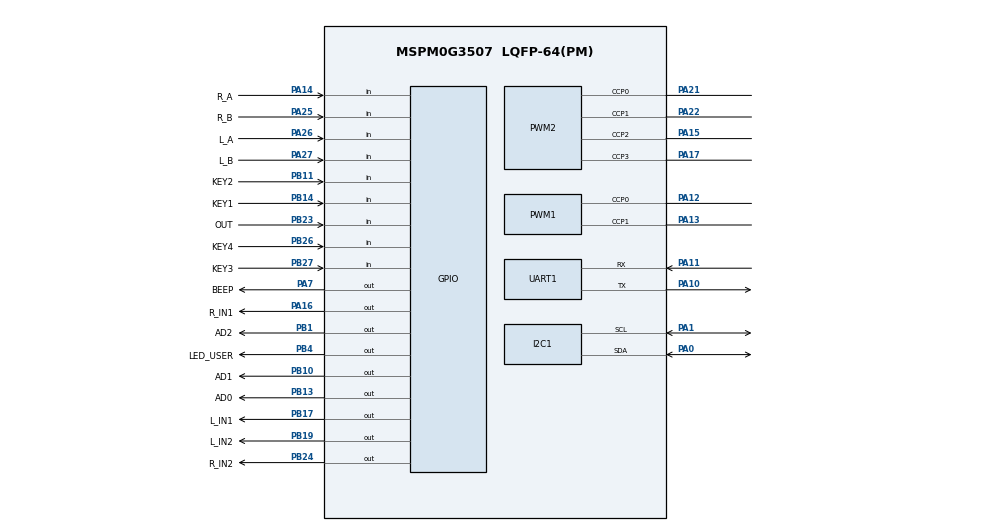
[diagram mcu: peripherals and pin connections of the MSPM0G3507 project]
/**
 * Revised local SysConfig script for the MSPM0G3507 E-car board.
 *
 * This file mirrors the checked-in ti_msp_dl_config.c/h logical names.
 * If SysConfig regenerates different macro names, keep App/Hardware code
 * mapped through Hardware/Board_Config.h.
 */
//@cliArgs --device "MSPM0G350X" --package "LQFP-64(PM)" --part "Default"
//@v2CliArgs --device "MSPM0G3507" --package "LQFP-64(PM)"
// @cliArgs --board /ti/boards/LP_MSPM0G3507 --rtos nortos

const GPIO   = scripting.addModule("/ti/driverlib/GPIO", {}, false);
const GPIO1  = GPIO.addInstance();
const GPIO2  = GPIO.addInstance();
const GPIO3  = GPIO.addInstance();
const GPIO4  = GPIO.addInstance();
const GPIO5  = GPIO.addInstance();
const I2C    = scripting.addModule("/ti/driverlib/I2C", {}, false);
const I2C1   = I2C.addInstance();
const PWM    = scripting.addModule("/ti/driverlib/PWM", {}, false);
const PWM1   = PWM.addInstance();
const PWM2   = PWM.addInstance();
const TIMER  = scripting.addModule("/ti/driverlib/TIMER", {}, false);
const TIMER1 = TIMER.addInstance();
const UART   = scripting.addModule("/ti/driverlib/UART", {}, false);
const UART1  = UART.addInstance();
const SYSCTL = scripting.addModule("/ti/driverlib/SYSCTL");

const Board = scripting.addModule("/ti/driverlib/Board", {}, false);

/*
 * TB6612:
 * PWMA = TIMG0-C0, PWMB = TIMG0-C1.
 * STBY is tied to 5V and is intentionally not configured as an MCU GPIO.
 */
GPIO1.$name = "GPIO_MOTOR";
GPIO1.associatedPins.create(4);
GPIO1.associatedPins[0].$name        = "L_IN1";
GPIO1.associatedPins[0].assignedPort = "PORTB";
GPIO1.associatedPins[0].assignedPin  = "17";
GPIO1.associatedPins[0].pin.$assign  = "PB17";
GPIO1.associatedPins[0].initialValue = "CLEARED";
GPIO1.associatedPins[1].$name        = "L_IN2";
GPIO1.associatedPins[1].assignedPort = "PORTB";
GPIO1.associatedPins[1].assignedPin  = "19";
GPIO1.associatedPins[1].pin.$assign  = "PB19";
GPIO1.associatedPins[1].initialValue = "CLEARED";
GPIO1.associatedPins[2].$name        = "R_IN1";
GPIO1.associatedPins[2].assignedPort = "PORTA";
GPIO1.associatedPins[2].assignedPin  = "16";
GPIO1.associatedPins[2].pin.$assign  = "PA16";
GPIO1.associatedPins[2].initialValue = "CLEARED";
GPIO1.associatedPins[3].$name        = "R_IN2";
GPIO1.associatedPins[3].assignedPort = "PORTB";
GPIO1.associatedPins[3].assignedPin  = "24";
GPIO1.associatedPins[3].pin.$assign  = "PB24";
GPIO1.associatedPins[3].initialValue = "CLEARED";

/*
 * Encoder first pass:
 * M1 = left, M2 = right.  A phase is interrupt input, B phase is sampled.
 * ENC_L_A/ENC_L_B = PA26/PA27, ENC_R_A/ENC_R_B = PA14/PA25.
 */
GPIO2.$name = "GPIO_ENCODER";
GPIO2.associatedPins.create(4);
GPIO2.associatedPins[0].$name            = "L_A";
GPIO2.associatedPins[0].assignedPort     = "PORTA";
GPIO2.associatedPins[0].assignedPin      = "26";
GPIO2.associatedPins[0].pin.$assign      = "PA26";
GPIO2.associatedPins[0].direction        = "INPUT";
GPIO2.associatedPins[0].internalResistor = "PULL_UP";
GPIO2.associatedPins[0].interruptEn      = true;
GPIO2.associatedPins[0].polarity         = "RISE_FALL";
GPIO2.associatedPins[1].$name            = "L_B";
GPIO2.associatedPins[1].assignedPort     = "PORTA";
GPIO2.associatedPins[1].assignedPin      = "27";
GPIO2.associatedPins[1].pin.$assign      = "PA27";
GPIO2.associatedPins[1].direction        = "INPUT";
GPIO2.associatedPins[1].internalResistor = "PULL_UP";
GPIO2.associatedPins[2].$name            = "R_A";
GPIO2.associatedPins[2].assignedPort     = "PORTA";
GPIO2.associatedPins[2].assignedPin      = "14";
GPIO2.associatedPins[2].pin.$assign      = "PA14";
GPIO2.associatedPins[2].direction        = "INPUT";
GPIO2.associatedPins[2].internalResistor = "PULL_UP";
GPIO2.associatedPins[2].interruptEn      = true;
GPIO2.associatedPins[2].polarity         = "RISE_FALL";
GPIO2.associatedPins[3].$name            = "R_B";
GPIO2.associatedPins[3].assignedPort     = "PORTA";
GPIO2.associatedPins[3].assignedPin      = "25";
GPIO2.associatedPins[3].pin.$assign      = "PA25";
GPIO2.associatedPins[3].direction        = "INPUT";
GPIO2.associatedPins[3].internalResistor = "PULL_UP";

/*
 * 8-channel grayscale module:
 * VCC = 5V.  GRAY_OUT must be divided/level-shifted to <= 3.3V before B23.
 * Software cannot make a direct 5V GPIO input safe.
 */
GPIO3.$name = "GPIO_GRAYSCALE";
GPIO3.associatedPins.create(4);
GPIO3.associatedPins[0].$name        = "AD2";
GPIO3.associatedPins[0].assignedPort = "PORTB";
GPIO3.associatedPins[0].assignedPin  = "1";
GPIO3.associatedPins[0].pin.$assign  = "PB1";
GPIO3.associatedPins[0].initialValue = "CLEARED";
GPIO3.associatedPins[1].$name        = "AD1";
GPIO3.associatedPins[1].assignedPort = "PORTB";
GPIO3.associatedPins[1].assignedPin  = "10";
GPIO3.associatedPins[1].pin.$assign  = "PB10";
GPIO3.associatedPins[1].initialValue = "CLEARED";
GPIO3.associatedPins[2].$name        = "AD0";
GPIO3.associatedPins[2].assignedPort = "PORTB";
GPIO3.associatedPins[2].assignedPin  = "13";
GPIO3.associatedPins[2].pin.$assign  = "PB13";
GPIO3.associatedPins[2].initialValue = "CLEARED";
GPIO3.associatedPins[3].$name            = "OUT";
GPIO3.associatedPins[3].assignedPort     = "PORTB";
GPIO3.associatedPins[3].assignedPin      = "23";
GPIO3.associatedPins[3].pin.$assign      = "PB23";
GPIO3.associatedPins[3].direction        = "INPUT";
GPIO3.associatedPins[3].internalResistor = "NONE";

GPIO4.$name = "GPIO_KEYS";
GPIO4.associatedPins.create(4);
GPIO4.associatedPins[0].$name            = "KEY1";
GPIO4.associatedPins[0].assignedPort     = "PORTB";
GPIO4.associatedPins[0].assignedPin      = "14";
GPIO4.associatedPins[0].pin.$assign      = "PB14";
GPIO4.associatedPins[0].direction        = "INPUT";
GPIO4.associatedPins[0].internalResistor = "PULL_UP";
GPIO4.associatedPins[1].$name            = "KEY2";
GPIO4.associatedPins[1].assignedPort     = "PORTB";
GPIO4.associatedPins[1].assignedPin      = "11";
GPIO4.associatedPins[1].pin.$assign      = "PB11";
GPIO4.associatedPins[1].direction        = "INPUT";
GPIO4.associatedPins[1].internalResistor = "PULL_UP";
GPIO4.associatedPins[2].$name            = "KEY3";
GPIO4.associatedPins[2].assignedPort     = "PORTB";
GPIO4.associatedPins[2].assignedPin      = "27";
GPIO4.associatedPins[2].pin.$assign      = "PB27";
GPIO4.associatedPins[2].direction        = "INPUT";
GPIO4.associatedPins[2].internalResistor = "PULL_UP";
GPIO4.associatedPins[3].$name            = "KEY4";
GPIO4.associatedPins[3].assignedPort     = "PORTB";
GPIO4.associatedPins[3].assignedPin      = "26";
GPIO4.associatedPins[3].pin.$assign      = "PB26";
GPIO4.associatedPins[3].direction        = "INPUT";
GPIO4.associatedPins[3].internalResistor = "PULL_UP";

GPIO5.$name = "GPIO_BOARD_IO";
GPIO5.associatedPins.create(2);
GPIO5.associatedPins[0].$name        = "LED_USER";
GPIO5.associatedPins[0].assignedPort = "PORTB";
GPIO5.associatedPins[0].assignedPin  = "4";
GPIO5.associatedPins[0].pin.$assign  = "PB4";
GPIO5.associatedPins[0].initialValue = "CLEARED";
GPIO5.associatedPins[1].$name        = "BEEP";
GPIO5.associatedPins[1].assignedPort = "PORTA";
GPIO5.associatedPins[1].assignedPin  = "7";
GPIO5.associatedPins[1].pin.$assign  = "PA7";
GPIO5.associatedPins[1].initialValue = "CLEARED";

PWM1.$name                      = "PWM_MOTOR";
PWM1.timerCount                 = 1600;
PWM1.peripheral.$assign         = "TIMG0";
PWM1.peripheral.ccp0Pin.$assign = "PA12";
PWM1.peripheral.ccp1Pin.$assign = "PA13";
PWM1.PWM_CHANNEL_0.$name        = "MOTOR_C0";
PWM1.PWM_CHANNEL_0.dutyCycle    = 0;
PWM1.PWM_CHANNEL_1.$name        = "MOTOR_C1";
PWM1.PWM_CHANNEL_1.dutyCycle    = 0;

/*
 * Servo PWM: TIMA0-C0..C3, 50Hz.  Physical H7/H15/H8/H14 connector routing
 * must be confirmed on the actual board before enabling ECAR_TEST_SERVO_ENABLE.
 */
PWM2.$name                      = "PWM_SERVO";
PWM2.ccIndex                    = [0,1,2,3];
PWM2.clockPrescale              = 32;
PWM2.timerCount                 = 20000;
PWM2.peripheral.$assign         = "TIMA0";
PWM2.peripheral.ccp0Pin.$assign = "PA21";
PWM2.peripheral.ccp1Pin.$assign = "PA22";
PWM2.peripheral.ccp2Pin.$assign = "PA15";
PWM2.peripheral.ccp3Pin.$assign = "PA17";
PWM2.PWM_CHANNEL_0.$name        = "SERVO_C0";
PWM2.PWM_CHANNEL_0.dutyCycle    = 0;
PWM2.PWM_CHANNEL_1.$name        = "SERVO_C1";
PWM2.PWM_CHANNEL_1.dutyCycle    = 0;
PWM2.PWM_CHANNEL_2.$name        = "SERVO_C2";
PWM2.PWM_CHANNEL_2.dutyCycle    = 0;
PWM2.PWM_CHANNEL_3.$name        = "SERVO_C3";
PWM2.PWM_CHANNEL_3.dutyCycle    = 0;

TIMER1.$name              = "TIMER_SYS";
TIMER1.profile            = "Basic_Periodic";
TIMER1.timerPeriod        = "1 ms";
TIMER1.peripheral.$assign = "TIMG6";

UART1.$name                    = "UART_DEBUG";
UART1.profile                  = "CONFIG_PROFILE_1";
UART1.peripheral.$assign       = "UART0";
UART1.targetBaudRate           = 115200;
UART1.enableInternalLoopback   = false;
UART1.enableFIFO              = false;
UART1.enabledInterrupts        = ["RX"];
UART1.peripheral.txPin.$assign = "PA10";
UART1.peripheral.rxPin.$assign = "PA11";

I2C1.$name                     = "I2C_SHARED";
I2C1.basicEnableController     = true;
I2C1.basicControllerBusSpeed   = 400000;
I2C1.advAnalogGlitchFilter     = "DISABLED";
I2C1.peripheral.$assign        = "I2C0";
I2C1.peripheral.sclPin.$assign = "PA1";
I2C1.peripheral.sdaPin.$assign = "PA0";

/* UART1/2/3 are reserved connectors in this board-test pass and are not
 * initialized here.  H21/H19 are one UART1 pair; H18/H20 are one UART2 pair.
 */

SYSCTL.forceDefaultClkConfig = true;
SYSCTL.clockTreeEn = true;
